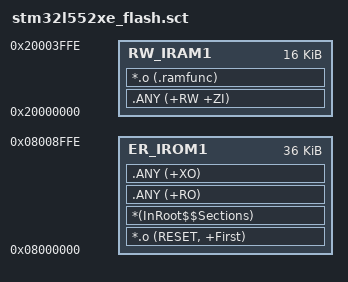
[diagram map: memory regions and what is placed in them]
; *************************************************************
; *** Scatter-Loading Description File generated by uVision ***
; *************************************************************

LR_IROM1 0x08000000 0x00008FFF  {    ; load region size_region
  ER_IROM1 0x08000000 0x00008FFF  {  ; load address = execution address
   *.o (RESET, +First)
   *(InRoot$$Sections)
   .ANY (+RO)
   .ANY (+XO)
  }
  RW_IRAM1 0x20000000 0x00003FFF  {  ; RW data
   .ANY (+RW +ZI)
   *.o (.ramfunc)  ; Used to place functions in RAM
  }
}

